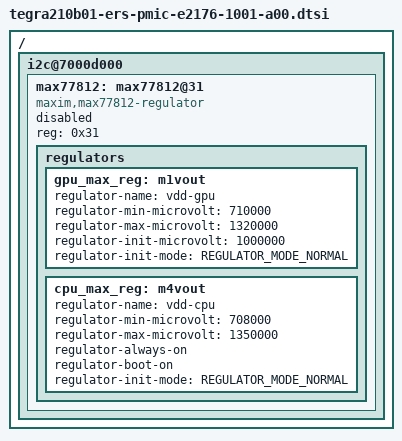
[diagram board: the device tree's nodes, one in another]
/*
 * Copyright (c) 2017, NVIDIA CORPORATION.  All rights reserved.
 *
 * This program is free software; you can redistribute it and/or modify
 * it under the terms of the GNU General Public License as published by
 * the Free Software Foundation; either version 2 of the License, or
 * (at your option) any later version.
 *
 * This program is distributed in the hope that it will be useful, but WITHOUT
 * ANY WARRANTY; without even the implied warranty of MERCHANTABILITY or
 * FITNESS FOR A PARTICULAR PURPOSE.  See the GNU General Public License for
 * more details.
 *
 * You should have received a copy of the GNU General Public License
 * along with this program.  If not, see <http://www.gnu.org/licenses/>.
 */

#include "tegra210b01-ers-pmic-e2175-1122-a00.dtsi"

/ {

	i2c@7000d000 {
		max77812: max77812@31 {
			compatible = "maxim,max77812-regulator";
			reg = <0x31>;
			status = "disabled";

			regulators {
				gpu_max_reg: m1vout {
					regulator-name = "vdd-gpu";
					regulator-min-microvolt = <710000>;
					regulator-max-microvolt = <1320000>;
					regulator-init-microvolt = <1000000>;
					regulator-init-mode = <REGULATOR_MODE_NORMAL>;
				};

				cpu_max_reg: m4vout {
					regulator-name = "vdd-cpu";
					regulator-min-microvolt = <708000>;
					regulator-max-microvolt = <1350000>;
					regulator-always-on;
					regulator-boot-on;
					regulator-init-mode = <REGULATOR_MODE_NORMAL>;
				};
			};
		};
	};
};
